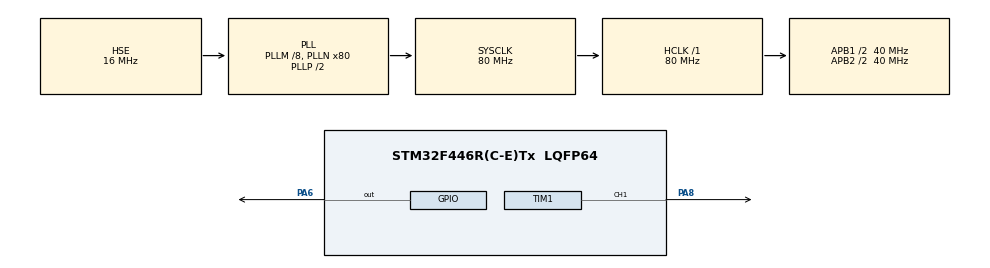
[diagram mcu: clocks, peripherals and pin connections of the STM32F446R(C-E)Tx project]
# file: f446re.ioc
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Dma.Request0=TIM1_CH1
Dma.TIM1_CH1.0.Direction=DMA_MEMORY_TO_PERIPH
Dma.TIM1_CH1.0.FIFOMode=DMA_FIFOMODE_DISABLE
Dma.TIM1_CH1.0.Instance=DMA2_Stream1
Dma.TIM1_CH1.0.MemDataAlignment=DMA_MDATAALIGN_WORD
Dma.TIM1_CH1.0.MemInc=DMA_MINC_ENABLE
Dma.TIM1_CH1.0.Mode=DMA_CIRCULAR
Dma.TIM1_CH1.0.PeriphDataAlignment=DMA_PDATAALIGN_WORD
Dma.TIM1_CH1.0.PeriphInc=DMA_PINC_DISABLE
Dma.TIM1_CH1.0.Priority=DMA_PRIORITY_LOW
Mcu.Family=STM32F4
Mcu.Name=STM32F446R(C-E)Tx
Mcu.Package=LQFP64
NVIC.DMA2_Stream1_IRQn=true\:0\:0\:false\:false\:true\:false\:true
NVIC.PriorityGroup=NVIC_PRIORITYGROUP_4
PA13.Mode=Serial_Wire
PA13.Signal=SYS_JTMS-SWDIO
PA14.Mode=Serial_Wire
PA14.Signal=SYS_JTCK-SWCLK
PA6.Signal=GPIO_Output
PA8.Signal=S_TIM1_CH1
PH0-OSC_IN.Mode=HSE-External-Oscillator
PH0-OSC_IN.Signal=RCC_OSC_IN
PH1-OSC_OUT.Mode=HSE-External-Oscillator
PH1-OSC_OUT.Signal=RCC_OSC_OUT
ProjectManager.HeapSize=0x200
ProjectManager.StackSize=0x400
ProjectManager.TargetToolchain=STM32CubeIDE
RCC.AHBFreq_Value=80000000
RCC.APB1CLKDivider=RCC_HCLK_DIV2
RCC.APB1Freq_Value=40000000
RCC.APB1TimFreq_Value=80000000
RCC.APB2CLKDivider=RCC_HCLK_DIV2
RCC.APB2Freq_Value=40000000
RCC.APB2TimFreq_Value=80000000
RCC.CortexFreq_Value=80000000
RCC.HCLKFreq_Value=80000000
RCC.HSE_VALUE=16000000
RCC.PLLM=8
RCC.PLLN=80
RCC.PLLSourceVirtual=RCC_PLLSOURCE_HSE
RCC.SYSCLKFreq_VALUE=80000000
RCC.SYSCLKSource=RCC_SYSCLKSOURCE_PLLCLK
RCC.USBFreq_Value=80000000
RCC.VCOOutputFreq_Value=160000000
SH.S_TIM1_CH1.0=TIM1_CH1,PWM Generation1 CH1
TIM1.Channel-PWM\ Generation1\ CH1=TIM_CHANNEL_1
TIM1.Period=104
board=custom

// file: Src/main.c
/* USER CODE BEGIN Header */
/**
  ******************************************************************************
  * @file           : main.c
  * @brief          : Main program body
  ******************************************************************************
  * @attention
  *
  * <h2><center>&copy; Copyright (c) 2019 STMicroelectronics.
  * All rights reserved.</center></h2>
  *
  * This software component is licensed by ST under BSD 3-Clause license,
  * the "License"; You may not use this file except in compliance with the
  * License. You may obtain a copy of the License at:
  *                        opensource.org/licenses/BSD-3-Clause
  *
  ******************************************************************************
  */
/* USER CODE END Header */

#include "main.h"
#include "dma.h"
#include "tim.h"
#include "gpio.h"

/* USER CODE BEGIN Includes */
#include "ws2812.h"
/* USER CODE END Includes */

void SystemClock_Config(void);

int main(void)
{

  /* MCU Configuration--------------------------------------------------------*/

  /* Reset of all peripherals, Initializes the Flash interface and the Systick. */
  HAL_Init();

  /* Configure the system clock */
  SystemClock_Config();

  /* Initialize all configured peripherals */
  MX_GPIO_Init();
  MX_DMA_Init();
  MX_TIM1_Init();
  /* USER CODE BEGIN 2 */

  uint32_t nowtick;
  uint32_t pasttick;
  ws2812Begin(8);

  uint32_t step = 0;
  /* USER CODE END 2 */

  /* Infinite loop */
    while (1)
    {

    /* USER CODE BEGIN 3 */
  	  HAL_GPIO_WritePin(GPIOA, GPIO_PIN_6, GPIO_PIN_SET);

  	  nowtick = HAL_GetTick();

		if (nowtick - pasttick > 10) {

//			for( uint32_t i = 0 ; i < 8; i ++)
//			{
//				if (led_color == 0)
//					ws2812SetColor(i, 255, 0, 0);
//				if (led_color == 1)
//					ws2812SetColor(i, 0, 255, 0);
//				if (led_color == 2)
//					ws2812SetColor(i, 0, 0, 255);
//			}
//			led_index = 0;//(led_index + 1) % 8;
//
//			if (led_index == 0) {
//				led_color = (led_color + 1) % 3;
//			}

			for(uint32_t i = 0; i < 24; i ++)
			{
				if(step == i)
					ws2812SetColor(i, 255, 0, 0);
				else
				{
					uint8_t factor = 128 >> (abs(step-i)*2);
					ws2812SetColor(i, factor, factor, factor);
				}

			}

			step++;
			if(step == 24)
				step = 0;

			pasttick = nowtick;
		}
    }
  /* USER CODE END 3 */
}

void SystemClock_Config(void)
{
  RCC_OscInitTypeDef RCC_OscInitStruct = {0};
  RCC_ClkInitTypeDef RCC_ClkInitStruct = {0};

  /** Configure the main internal regulator output voltage
  */
  __HAL_RCC_PWR_CLK_ENABLE();
  __HAL_PWR_VOLTAGESCALING_CONFIG(PWR_REGULATOR_VOLTAGE_SCALE3);
  /** Initializes the CPU, AHB and APB busses clocks
  */
  RCC_OscInitStruct.OscillatorType = RCC_OSCILLATORTYPE_HSE;
  RCC_OscInitStruct.HSEState = RCC_HSE_ON;
  RCC_OscInitStruct.PLL.PLLState = RCC_PLL_ON;
  RCC_OscInitStruct.PLL.PLLSource = RCC_PLLSOURCE_HSE;
  RCC_OscInitStruct.PLL.PLLM = 8;
  RCC_OscInitStruct.PLL.PLLN = 80;
  RCC_OscInitStruct.PLL.PLLP = RCC_PLLP_DIV2;
  RCC_OscInitStruct.PLL.PLLQ = 2;
  RCC_OscInitStruct.PLL.PLLR = 2;
  if (HAL_RCC_OscConfig(&RCC_OscInitStruct) != HAL_OK)
  {
    Error_Handler();
  }
  /** Initializes the CPU, AHB and APB busses clocks
  */
  RCC_ClkInitStruct.ClockType = RCC_CLOCKTYPE_HCLK|RCC_CLOCKTYPE_SYSCLK
                              |RCC_CLOCKTYPE_PCLK1|RCC_CLOCKTYPE_PCLK2;
  RCC_ClkInitStruct.SYSCLKSource = RCC_SYSCLKSOURCE_PLLCLK;
  RCC_ClkInitStruct.AHBCLKDivider = RCC_SYSCLK_DIV1;
  RCC_ClkInitStruct.APB1CLKDivider = RCC_HCLK_DIV2;
  RCC_ClkInitStruct.APB2CLKDivider = RCC_HCLK_DIV2;

  if (HAL_RCC_ClockConfig(&RCC_ClkInitStruct, FLASH_LATENCY_2) != HAL_OK)
  {
    Error_Handler();
  }
}

void Error_Handler(void)
{
}

/************************ (C) COPYRIGHT STMicroelectronics *****END OF FILE****/
